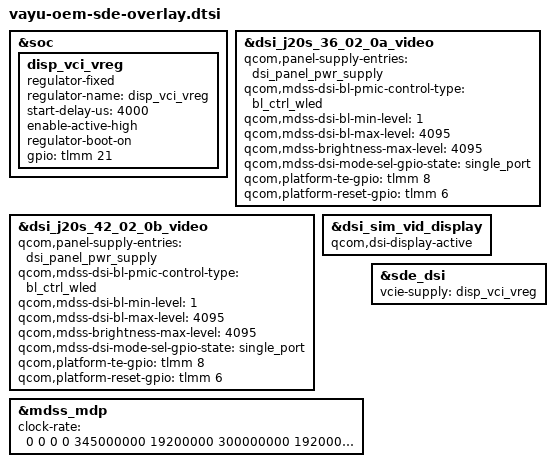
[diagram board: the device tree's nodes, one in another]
/* Copyright (c) 2021, The Linux Foundation. All rights reserved.
*  Copyright (c) 2021, Jebaitedneko <Jebaitedneko@gmail.com>.
*
* This program is free software; you can redistribute it and/or modify
* it under the terms of the GNU General Public License version 2 and
* only version 2 as published by the Free Software Foundation.
*
* This program is distributed in the hope that it will be useful,
* but WITHOUT ANY WARRANTY; without even the implied warranty of
* MERCHANTABILITY or FITNESS FOR A PARTICULAR PURPOSE.  See the
* GNU General Public License for more details.
*/

&soc {
	disp_vci_vreg: disp_vci_vreg {
		compatible = "regulator-fixed";
		regulator-name = "disp_vci_vreg";
		start-delay-us = <4000>;
		enable-active-high;
		regulator-boot-on;
		gpio = <&tlmm 21 0>;
	};
};

&dsi_j20s_36_02_0a_video {
	qcom,panel-supply-entries = <&dsi_panel_pwr_supply>;
	qcom,mdss-dsi-bl-pmic-control-type = "bl_ctrl_wled";
	qcom,mdss-dsi-bl-min-level = <1>;
	qcom,mdss-dsi-bl-max-level = <4095>;
	qcom,mdss-brightness-max-level = <4095>;
	qcom,mdss-dsi-mode-sel-gpio-state = "single_port";
	qcom,platform-te-gpio = <&tlmm 8 0>;
	qcom,platform-reset-gpio = <&tlmm 6 0>;
};

&dsi_j20s_42_02_0b_video {
	qcom,panel-supply-entries = <&dsi_panel_pwr_supply>;
	qcom,mdss-dsi-bl-pmic-control-type = "bl_ctrl_wled";
	qcom,mdss-dsi-bl-min-level = <1>;
	qcom,mdss-dsi-bl-max-level = <4095>;
	qcom,mdss-brightness-max-level = <4095>;
	qcom,mdss-dsi-mode-sel-gpio-state = "single_port";
	qcom,platform-te-gpio = <&tlmm 8 0>;
	qcom,platform-reset-gpio = <&tlmm 6 0>;
};

&dsi_sim_vid_display {
	qcom,dsi-display-active;
};

&mdss_mdp {
	clock-rate = <0 0 0 0 345000000 19200000 300000000 19200000>;
};

&sde_dsi {
	vcie-supply = <&disp_vci_vreg>;
};
